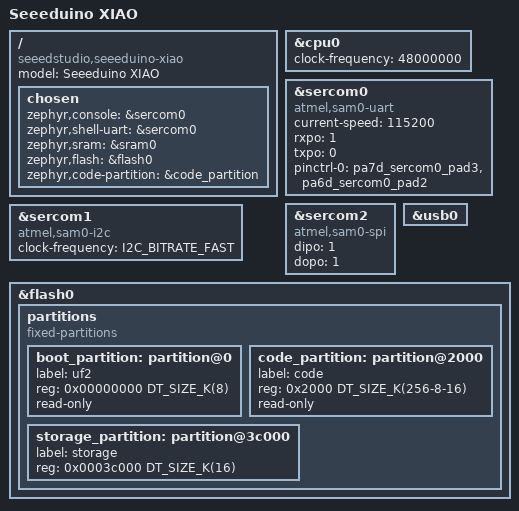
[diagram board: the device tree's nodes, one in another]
/*
 * Copyright (c) 2020 Google LLC.
 *
 * SPDX-License-Identifier: Apache-2.0
 */

/dts-v1/;
#include <atmel/samd21.dtsi>
#include "seeed_xiao_connector.dtsi"

/ {
	model = "Seeeduino XIAO";
	compatible = "seeedstudio,seeeduino-xiao";

	chosen {
		zephyr,console = &sercom0;
		zephyr,shell-uart = &sercom0;
		zephyr,sram = &sram0;
		zephyr,flash = &flash0;
		zephyr,code-partition = &code_partition;
	};

};

&cpu0 {
	clock-frequency = <48000000>;
};

&sercom0 {
	status = "okay";
	compatible = "atmel,sam0-uart";
	current-speed = <115200>;
	rxpo = <1>;
	txpo = <0>;

	pinctrl-0 = <&pa7d_sercom0_pad3 &pa6d_sercom0_pad2>;
};

&sercom2 {
	status = "okay";
	compatible = "atmel,sam0-spi";
	dipo = <1>;
	dopo = <1>;
	#address-cells = <1>;
	#size-cells = <0>;
};

&sercom1 {
	status = "okay";
	compatible = "atmel,sam0-i2c";
	clock-frequency = <I2C_BITRATE_FAST>;
	#address-cells = <1>;
	#size-cells = <0>;
};

zephyr_udc0: &usb0 {
	status = "okay";
};

&flash0 {
	partitions {
		compatible = "fixed-partitions";
		#address-cells = <1>;
		#size-cells = <1>;

		boot_partition: partition@0 {
			label = "uf2";
			reg = <0x00000000 DT_SIZE_K(8)>;
			read-only;
		};

		code_partition: partition@2000 {
			label = "code";
			reg = <0x2000 DT_SIZE_K(256-8-16)>;
			read-only;
		};

		/*
		 * The final 16 KiB is reserved for the application.
		 * Storage partition may be used by FCB or LittleFS.
		 */
		storage_partition: partition@3c000 {
			label = "storage";
			reg = <0x0003c000 DT_SIZE_K(16)>;
		};
	};
};
